# STM32H745_CM7 register map
File version: 2.5
CPU: CM7 r0p1, little endian, MPU, FPU, 4 interrupt priority bits
Registers are 32-bit, read-write, reset 0x0 unless marked. A register's access mark holds for its fields unless they carry their own. Offsets are from the block's base; [hi:lo] are bit positions; {n}, {i} and the like mark numbered series; 'fields as' and 'values as' point back to an identical list.

## COMP1
Base 0x58003800
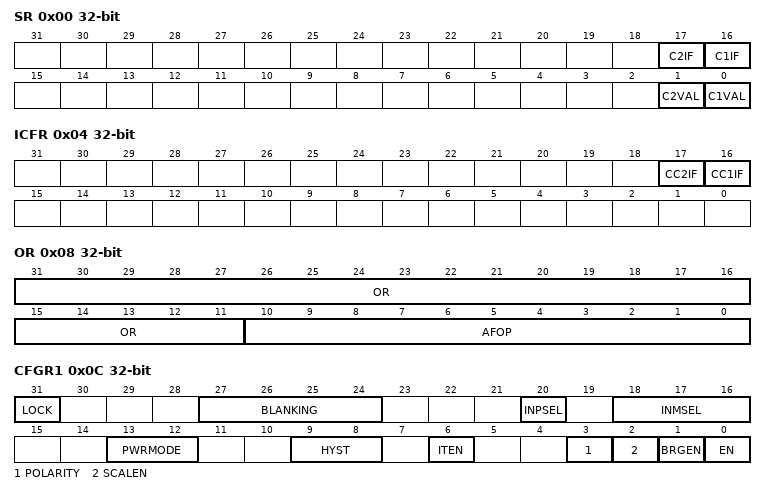
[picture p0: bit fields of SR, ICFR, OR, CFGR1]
0x00 SR ro — Comparator status register
  [17] C2IF — COMP channel 2 Interrupt Flag
  [16] C1IF — COMP channel 1 Interrupt Flag
  [1] C2VAL — COMP channel 2 output status bit
  [0] C1VAL — COMP channel 1 output status bit
0x04 ICFR wo — Comparator interrupt clear flag register
  [17] CC2IF — Clear COMP channel 2 Interrupt Flag
  [16] CC1IF — Clear COMP channel 1 Interrupt Flag
0x08 OR — Comparator option register
  [31:11] OR — Option Register
  [10:0] AFOP — Selection of source for alternate function of output ports
0x0C CFGR1 — Comparator configuration register 1
  [31] LOCK — Lock bit
  [27:24] BLANKING — COMP channel 1 blanking source selection bits
  [20] INPSEL — COMP channel 1 non-inverting input selection bit
  [18:16] INMSEL — COMP channel 1 inverting input selection field
  [13:12] PWRMODE — Power Mode of the COMP channel 1
  [9:8] HYST — COMP channel 1 hysteresis selection bits
  [6] ITEN — COMP channel 1 interrupt enable
  [3] POLARITY — COMP channel 1 polarity selection bit
  [2] SCALEN — Voltage scaler enable bit
  [1] BRGEN — Scaler bridge enable
  [0] EN — COMP channel 1 enable bit
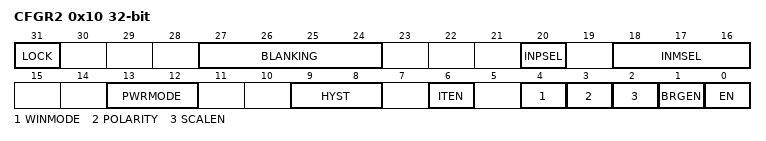
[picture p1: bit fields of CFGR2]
0x10 CFGR2 — Comparator configuration register 2
  [31] LOCK — Lock bit
  [27:24] BLANKING — COMP channel 1 blanking source selection bits
  [20] INPSEL — COMP channel 1 non-inverting input selection bit
  [18:16] INMSEL — COMP channel 1 inverting input selection field
  [13:12] PWRMODE — Power Mode of the COMP channel 1
  [9:8] HYST — COMP channel 1 hysteresis selection bits
  [6] ITEN — COMP channel 1 interrupt enable
  [4] WINMODE — Window comparator mode selection bit
  [3] POLARITY — COMP channel 1 polarity selection bit
  [2] SCALEN — Voltage scaler enable bit
  [1] BRGEN — Scaler bridge enable
  [0] EN — COMP channel 1 enable bit

## HSEM
Base 0x58026400
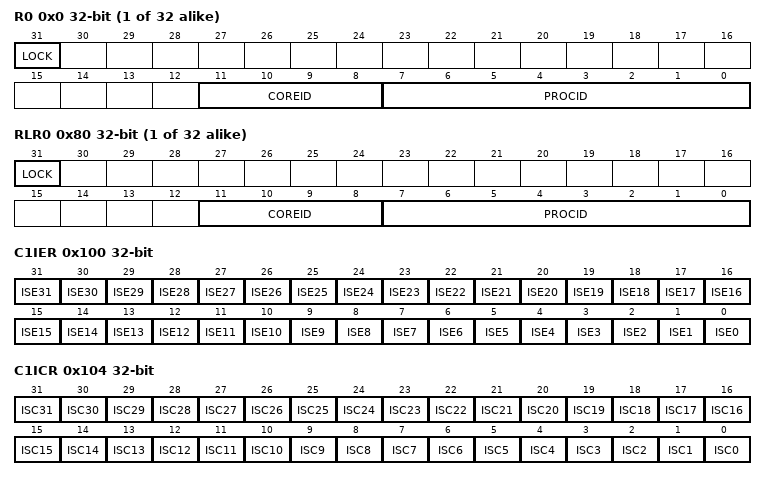
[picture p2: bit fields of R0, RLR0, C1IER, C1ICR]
{0x0+4i} R{i} (i=0..31) — HSEM register HSEM_R{i}
  [31] LOCK — Lock indication
    on read: 0=Free (Semaphore is free); 1=Locked (Semaphore is locked) | on write: 0=Free semaphore; 1=TryLock (Try to lock semaphore)
  [11:8] COREID — Semaphore COREID
  [7:0] PROCID — Semaphore ProcessID
{0x80+4i} RLR{i} (i=0..31) ro — Semaphore {i} read lock register
  [31] LOCK — Lock indication
    0=Free (Semaphore is free); 1=Locked (Semaphore is locked)
  [11:8] COREID — Semaphore COREID
  [7:0] PROCID — Semaphore ProcessID
0x100 C1IER — HSEM Interrupt enable register
  [n] ISE{n} (n=0..31) — Interrupt semaphore {n} enable bit
    0=Disabled (Interrupt generation disabled); 1=Enabled (Interrupt generation enabled)
0x104 C1ICR — HSEM Interrupt clear register
  [n] ISC{n} (n=0..31) — Interrupt semaphore {n} clear bit
    on read: 0=NoEffect (Always reads 0) | on write: 0=NoEffect (Interrupt semaphore x status ISFx and masked status MISFx not affected); 1=Clear (Interrupt semaphore x status ISFx and masked status MISFx cleared)
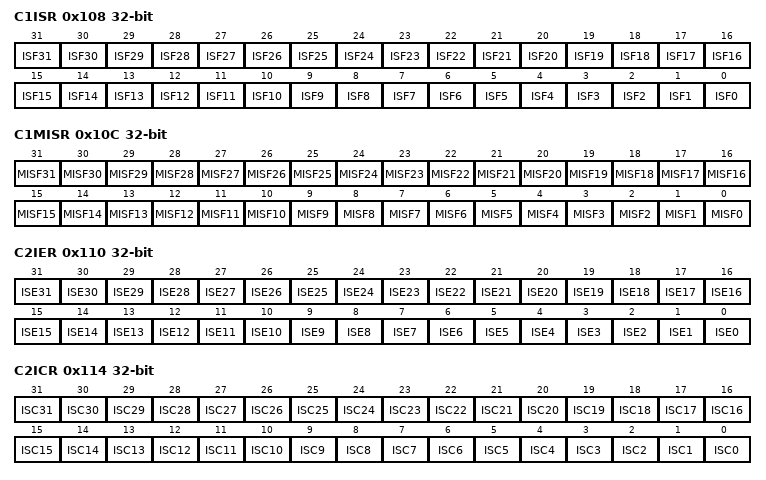
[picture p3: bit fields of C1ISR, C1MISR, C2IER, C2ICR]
0x108 C1ISR ro — HSEM Interrupt status register
  [n] ISF{n} (n=0..31) — Interrupt semaphore {n} status bit before enable (mask)
    0=NotPending (No interrupt pending); 1=Pending (Interrupt pending)
0x10C C1MISR ro — HSEM Masked interrupt status register
  [n] MISF{n} (n=0..31) — Masked interrupt semaphore {n} status bit after enable (mask)
    0=NotPending (No interrupt pending after masking); 1=Pending (Interrupt pending after masking)
0x110 C2IER — HSEM Interrupt enable register
  fields as C1IER
0x114 C2ICR — HSEM Interrupt clear register
  fields as C1ICR
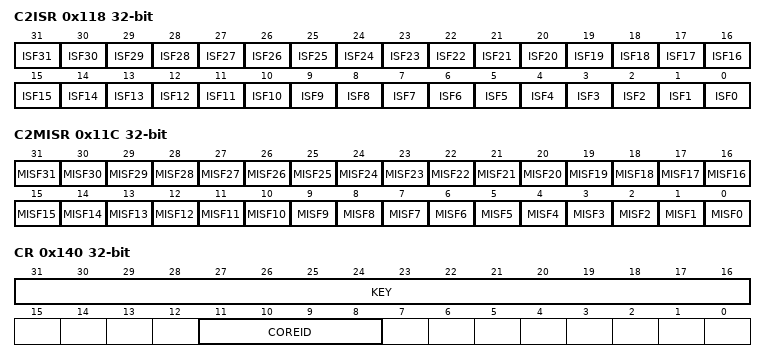
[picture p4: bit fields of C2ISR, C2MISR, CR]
0x118 C2ISR ro — HSEM Interrupt status register
  fields as C1ISR
0x11C C2MISR ro — HSEM Masked interrupt status register
  fields as C1MISR
0x140 CR wo — HSEM Clear register
  [31:16] KEY — Semaphore clear Key
  [11:8] COREID — COREID of semaphores to be cleared
0x144 KEYR — HSEM Interrupt clear register
  [31:16] KEY — Semaphore Clear Key
